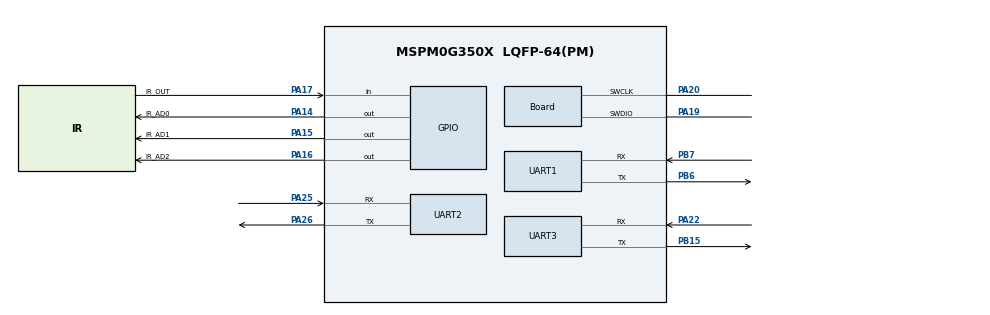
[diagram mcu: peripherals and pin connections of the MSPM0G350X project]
/**
 * @cliArgs --device "MSPM0G350X" --part "Default" --package "LQFP-64(PM)" --product "mspm0_sdk@2.11.00.07"
 * @versions {"tool":"1.26.2+4477"}
 */

/**
 * Import the modules used in this configuration.
 */
const GPIO          = scripting.addModule("/ti/driverlib/GPIO", {}, false);
const GPIO1         = GPIO.addInstance();
const SYSCTL        = scripting.addModule("/ti/driverlib/SYSCTL");
const UART          = scripting.addModule("/ti/driverlib/UART", {}, false);
const UART1         = UART.addInstance();
const UART2         = UART.addInstance();
const UART3         = UART.addInstance();
const ProjectConfig = scripting.addModule("/ti/project_config/ProjectConfig");

/**
 * Write custom configuration values to the imported modules.
 */
GPIO1.$name                         = "IR_GPIO";
GPIO1.associatedPins.create(4);
GPIO1.associatedPins[0].$name       = "IR_AD0";
GPIO1.associatedPins[0].pin.$assign = "PA14";
GPIO1.associatedPins[1].$name       = "IR_AD1";
GPIO1.associatedPins[1].pin.$assign = "PA15";
GPIO1.associatedPins[2].$name       = "IR_AD2";
GPIO1.associatedPins[2].pin.$assign = "PA16";
GPIO1.associatedPins[3].$name       = "IR_OUT";
GPIO1.associatedPins[3].direction   = "INPUT";
GPIO1.associatedPins[3].pin.$assign = "PA17";

const Board                       = scripting.addModule("/ti/driverlib/Board", {}, false);
Board.peripheral.$assign          = "DEBUGSS";
Board.peripheral.swclkPin.$assign = "PA20";
Board.peripheral.swdioPin.$assign = "PA19";

SYSCTL.clockTreeEn = true;

UART1.targetBaudRate                   = 115200;
UART1.enableFIFO                       = true;
UART1.rxFifoThreshold                  = "DL_UART_RX_FIFO_LEVEL_ONE_ENTRY";
UART1.enableDMARX                      = false;
UART1.enableDMATX                      = false;
UART1.$name                            = "UART_1";
UART1.peripheral.$assign               = "UART1";
UART1.peripheral.rxPin.$assign         = "PB7";
UART1.peripheral.txPin.$assign         = "PB6";
UART1.txPinConfig.direction            = scripting.forceWrite("OUTPUT");
UART1.txPinConfig.hideOutputInversion  = scripting.forceWrite(false);
UART1.txPinConfig.onlyInternalResistor = scripting.forceWrite(false);
UART1.txPinConfig.passedPeripheralType = scripting.forceWrite("Digital");
UART1.txPinConfig.$name                = "ti_driverlib_gpio_GPIOPinGeneric2";
UART1.rxPinConfig.hideOutputInversion  = scripting.forceWrite(false);
UART1.rxPinConfig.onlyInternalResistor = scripting.forceWrite(false);
UART1.rxPinConfig.passedPeripheralType = scripting.forceWrite("Digital");
UART1.rxPinConfig.$name                = "ti_driverlib_gpio_GPIOPinGeneric3";

UART2.targetBaudRate                   = 115200;
UART2.$name                            = "UART_IMU";
UART2.enableFIFO                       = true;
UART2.enabledInterrupts                = ["RX"];
UART2.rxFifoThreshold                  = "DL_UART_RX_FIFO_LEVEL_ONE_ENTRY";
UART2.peripheral.rxPin.$assign         = "PA25";
UART2.peripheral.txPin.$assign         = "PA26";
UART2.txPinConfig.direction            = scripting.forceWrite("OUTPUT");
UART2.txPinConfig.hideOutputInversion  = scripting.forceWrite(false);
UART2.txPinConfig.onlyInternalResistor = scripting.forceWrite(false);
UART2.txPinConfig.passedPeripheralType = scripting.forceWrite("Digital");
UART2.txPinConfig.$name                = "ti_driverlib_gpio_GPIOPinGeneric4";
UART2.rxPinConfig.hideOutputInversion  = scripting.forceWrite(false);
UART2.rxPinConfig.onlyInternalResistor = scripting.forceWrite(false);
UART2.rxPinConfig.passedPeripheralType = scripting.forceWrite("Digital");
UART2.rxPinConfig.$name                = "ti_driverlib_gpio_GPIOPinGeneric5";

UART3.$name                            = "UART_K230";
UART3.targetBaudRate                   = 115200;
UART3.enabledInterrupts                = ["RX"];
UART3.peripheral.$assign               = "UART2";
UART3.peripheral.rxPin.$assign         = "PA22";
UART3.peripheral.txPin.$assign         = "PB15";
UART3.txPinConfig.direction            = scripting.forceWrite("OUTPUT");
UART3.txPinConfig.hideOutputInversion  = scripting.forceWrite(false);
UART3.txPinConfig.onlyInternalResistor = scripting.forceWrite(false);
UART3.txPinConfig.passedPeripheralType = scripting.forceWrite("Digital");
UART3.txPinConfig.$name                = "ti_driverlib_gpio_GPIOPinGeneric6";
UART3.rxPinConfig.hideOutputInversion  = scripting.forceWrite(false);
UART3.rxPinConfig.onlyInternalResistor = scripting.forceWrite(false);
UART3.rxPinConfig.passedPeripheralType = scripting.forceWrite("Digital");
UART3.rxPinConfig.$name                = "ti_driverlib_gpio_GPIOPinGeneric7";

ProjectConfig.deviceSpin = "MSPM0G3507";

/**
 * Pinmux solution for unlocked pins/peripherals. This ensures that minor changes to the automatic solver in a future
 * version of the tool will not impact the pinmux you originally saw.  These lines can be completely deleted in order to
 * re-solve from scratch.
 */
UART2.peripheral.$suggestSolution = "UART3";
